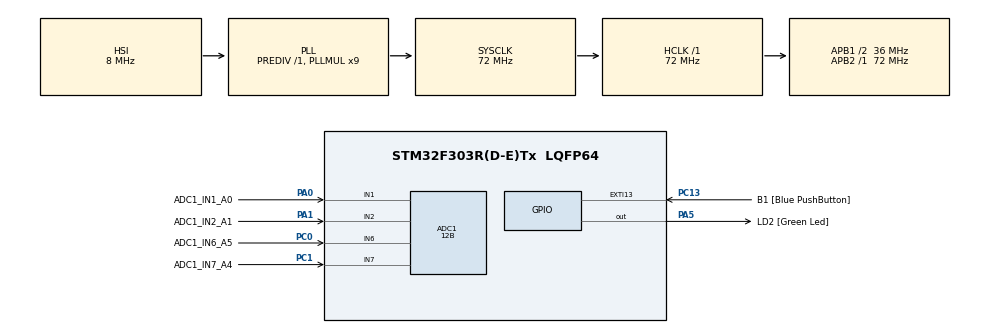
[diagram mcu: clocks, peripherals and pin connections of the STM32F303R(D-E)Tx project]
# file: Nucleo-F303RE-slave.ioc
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ADC1.Channel-0\#ChannelRegularConversion=ADC_CHANNEL_1
ADC1.Channel-1\#ChannelRegularConversion=ADC_CHANNEL_2
ADC1.Channel-2\#ChannelRegularConversion=ADC_CHANNEL_7
ADC1.Channel-3\#ChannelRegularConversion=ADC_CHANNEL_6
ADC1.ClockPrescaler=ADC_CLOCK_ASYNC_DIV1
ADC1.ContinuousConvMode=DISABLE
ADC1.DMAContinuousRequests=ENABLE
ADC1.EOCSelection=ADC_EOC_SEQ_CONV
ADC1.EnableInjectedConversion=DISABLE
ADC1.ExternalTrigConv=ADC_EXTERNALTRIGCONV_T1_CC3
ADC1.ExternalTrigConvEdge=ADC_EXTERNALTRIGCONVEDGE_RISINGFALLING
ADC1.NbrOfConversion=4
ADC1.NbrOfConversionFlag=1
ADC1.Offset-1\#ChannelRegularConversion=0
ADC1.Offset-2\#ChannelRegularConversion=0
ADC1.Offset-3\#ChannelRegularConversion=0
ADC1.OffsetNumber-1\#ChannelRegularConversion=ADC_OFFSET_NONE
ADC1.OffsetNumber-2\#ChannelRegularConversion=ADC_OFFSET_NONE
ADC1.OffsetNumber-3\#ChannelRegularConversion=ADC_OFFSET_NONE
ADC1.Rank-1\#ChannelRegularConversion=2
ADC1.Rank-2\#ChannelRegularConversion=3
ADC1.Rank-3\#ChannelRegularConversion=4
ADC1.Resolution=ADC_RESOLUTION_12B
ADC1.SamplingTime-0\#ChannelRegularConversion=ADC_SAMPLETIME_601CYCLES_5
ADC1.SamplingTime-1\#ChannelRegularConversion=ADC_SAMPLETIME_601CYCLES_5
ADC1.SamplingTime-2\#ChannelRegularConversion=ADC_SAMPLETIME_601CYCLES_5
ADC1.SamplingTime-3\#ChannelRegularConversion=ADC_SAMPLETIME_601CYCLES_5
ADC1.SamplingTimeOPAMP-2\#ChannelRegularConversion=ADC_SAMPLETIME_61CYCLES_5
ADC1.SamplingTimeOPAMP-3\#ChannelRegularConversion=ADC_SAMPLETIME_61CYCLES_5
ADC1.SequencerNbRanks=1
ADC1.master=1
Dma.ADC1.0.Direction=DMA_PERIPH_TO_MEMORY
Dma.ADC1.0.Instance=DMA1_Channel1
Dma.ADC1.0.MemDataAlignment=DMA_MDATAALIGN_HALFWORD
Dma.ADC1.0.MemInc=DMA_MINC_ENABLE
Dma.ADC1.0.Mode=DMA_CIRCULAR
Dma.ADC1.0.PeriphDataAlignment=DMA_PDATAALIGN_HALFWORD
Dma.ADC1.0.PeriphInc=DMA_PINC_DISABLE
Dma.ADC1.0.Priority=DMA_PRIORITY_LOW
Dma.Request0=ADC1
Mcu.Family=STM32F3
Mcu.Name=STM32F303R(D-E)Tx
Mcu.Package=LQFP64
NVIC.DMA1_Channel1_IRQn=true\:0\:0\:false\:false\:true\:false\:true
NVIC.PriorityGroup=NVIC_PRIORITYGROUP_4
PA0.GPIO_Label=ADC1_IN1_A0
PA0.GPIO_Mode=GPIO_MODE_ANALOG
PA0.GPIO_PuPd=GPIO_NOPULL
PA0.Mode=IN1-Single-Ended
PA0.Signal=ADC1_IN1
PA1.GPIO_Label=ADC1_IN2_A1
PA1.Mode=IN2-Single-Ended
PA1.Signal=ADC1_IN2
PA13.GPIO_Label=TMS
PA13.Mode=Serial_Wire
PA13.Signal=SYS_JTMS-SWDIO
PA14.GPIO_Label=TCK
PA14.Mode=Serial_Wire
PA14.Signal=SYS_JTCK-SWCLK
PA5.GPIO_Label=LD2 [Green Led]
PA5.GPIO_Mode=GPIO_MODE_OUTPUT_PP
PA5.GPIO_PuPd=GPIO_NOPULL
PA5.GPIO_Speed=GPIO_SPEED_FREQ_LOW
PA5.Signal=GPIO_Output
PB3.GPIO_Label=SWO
PB3.Signal=SYS_JTDO-TRACESWO
PC0.GPIO_Label=ADC1_IN6_A5
PC0.Signal=ADCx_IN6
PC1.GPIO_Label=ADC1_IN7_A4
PC1.Signal=ADCx_IN7
PC13.GPIO_Label=B1 [Blue PushButton]
PC13.GPIO_ModeDefaultEXTI=GPIO_MODE_IT_FALLING
PC13.Signal=GPXTI13
PC14-OSC32_IN.Mode=LSE-External-Oscillator
PC14-OSC32_IN.Signal=RCC_OSC32_IN
PC15-OSC32_OUT.Mode=LSE-External-Oscillator
PC15-OSC32_OUT.Signal=RCC_OSC32_OUT
PF0-OSC_IN.Mode=HSE-External-Clock-Source
PF0-OSC_IN.Signal=RCC_OSC_IN
PF1-OSC_OUT.Signal=RCC_OSC_OUT
ProjectManager.HeapSize=0x200
ProjectManager.StackSize=0x400
ProjectManager.TargetToolchain=STM32CubeIDE
RCC.AHBFreq_Value=72000000
RCC.APB1CLKDivider=RCC_HCLK_DIV2
RCC.APB1Freq_Value=36000000
RCC.APB1TimFreq_Value=72000000
RCC.APB2Freq_Value=72000000
RCC.APB2TimFreq_Value=72000000
RCC.CortexFreq_Value=72000000
RCC.HCLKFreq_Value=72000000
RCC.HSE_VALUE=8000000
RCC.HSI_VALUE=8000000
RCC.PLLM=8
RCC.PLLMUL=RCC_PLL_MUL9
RCC.PLLN=336
RCC.PLLP=RCC_PLLP_DIV4
RCC.PLLQ=7
RCC.RCC_PLLsource_Clock_Source_FROM_HSE=RCC_HSE_PREDIV_DIV2
RCC.SYSCLKFreq_VALUE=72000000
RCC.SYSCLKSourceVirtual=RCC_SYSCLKSOURCE_PLLCLK
RCC.USBFreq_Value=72000000
SH.ADCx_IN6.0=ADC1_IN6,IN6-Single-Ended
SH.ADCx_IN7.0=ADC1_IN7,IN7-Single-Ended
TIM1.AutoReloadPreload=TIM_AUTORELOAD_PRELOAD_ENABLE
TIM1.Channel-Output\ Compare3\ No\ Output=TIM_CHANNEL_3
TIM1.OCMode_3=TIM_OCMODE_TOGGLE
TIM1.Period=99
TIM1.Prescaler=71
VP_TIM1_VS_ClockSourceINT.Mode=Internal
VP_TIM1_VS_no_output3.Mode=Output Compare3 No Output
board=NUCLEO-F303RE

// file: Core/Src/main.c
/* USER CODE BEGIN Header */
/**
  ******************************************************************************
  * @file           : main.c
  * @brief          : Main program body
  ******************************************************************************
  * @attention
  *
  * <h2><center>&copy; Copyright (c) 2021 STMicroelectronics.
  * All rights reserved.</center></h2>
  *
  * This software component is licensed by ST under BSD 3-Clause license,
  * the "License"; You may not use this file except in compliance with the
  * License. You may obtain a copy of the License at:
  *                        opensource.org/licenses/BSD-3-Clause
  *
  ******************************************************************************
  */
/* USER CODE END Header */
#include "main.h"

ADC_HandleTypeDef hadc1;
DMA_HandleTypeDef hdma_adc1;

TIM_HandleTypeDef htim1;

/* USER CODE BEGIN PV */
extern void multimeter_meas(void);
/* USER CODE END PV */

void SystemClock_Config(void);
static void MX_GPIO_Init(void);
static void MX_DMA_Init(void);
static void MX_ADC1_Init(void);
static void MX_TIM1_Init(void);

int main(void)
{

  /* MCU Configuration--------------------------------------------------------*/

  /* Reset of all peripherals, Initializes the Flash interface and the Systick. */
  HAL_Init();

  /* Configure the system clock */
  SystemClock_Config();

  /* Initialize all configured peripherals */
  MX_GPIO_Init();
  MX_DMA_Init();
  MX_ADC1_Init();
  MX_TIM1_Init();
  /* USER CODE BEGIN 2 */
  multimeter_meas();
  /* USER CODE END 2 */

  /* Infinite loop */
  while (1)
  {

  }
}

void SystemClock_Config(void)
{
  RCC_OscInitTypeDef RCC_OscInitStruct = {0};
  RCC_ClkInitTypeDef RCC_ClkInitStruct = {0};
  RCC_PeriphCLKInitTypeDef PeriphClkInit = {0};

  /** Initializes the RCC Oscillators according to the specified parameters
  * in the RCC_OscInitTypeDef structure.
  */
  RCC_OscInitStruct.OscillatorType = RCC_OSCILLATORTYPE_HSI;
  RCC_OscInitStruct.HSIState = RCC_HSI_ON;
  RCC_OscInitStruct.HSICalibrationValue = RCC_HSICALIBRATION_DEFAULT;
  RCC_OscInitStruct.PLL.PLLState = RCC_PLL_ON;
  RCC_OscInitStruct.PLL.PLLSource = RCC_PLLSOURCE_HSI;
  RCC_OscInitStruct.PLL.PLLMUL = RCC_PLL_MUL9;
  RCC_OscInitStruct.PLL.PREDIV = RCC_PREDIV_DIV1;
  if (HAL_RCC_OscConfig(&RCC_OscInitStruct) != HAL_OK)
  {
    Error_Handler();
  }
  /** Initializes the CPU, AHB and APB buses clocks
  */
  RCC_ClkInitStruct.ClockType = RCC_CLOCKTYPE_HCLK|RCC_CLOCKTYPE_SYSCLK
                              |RCC_CLOCKTYPE_PCLK1|RCC_CLOCKTYPE_PCLK2;
  RCC_ClkInitStruct.SYSCLKSource = RCC_SYSCLKSOURCE_PLLCLK;
  RCC_ClkInitStruct.AHBCLKDivider = RCC_SYSCLK_DIV1;
  RCC_ClkInitStruct.APB1CLKDivider = RCC_HCLK_DIV2;
  RCC_ClkInitStruct.APB2CLKDivider = RCC_HCLK_DIV1;

  if (HAL_RCC_ClockConfig(&RCC_ClkInitStruct, FLASH_LATENCY_2) != HAL_OK)
  {
    Error_Handler();
  }
  PeriphClkInit.PeriphClockSelection = RCC_PERIPHCLK_TIM1|RCC_PERIPHCLK_ADC12;
  PeriphClkInit.Adc12ClockSelection = RCC_ADC12PLLCLK_DIV1;
  PeriphClkInit.Tim1ClockSelection = RCC_TIM1CLK_HCLK;
  if (HAL_RCCEx_PeriphCLKConfig(&PeriphClkInit) != HAL_OK)
  {
    Error_Handler();
  }
}

static void MX_ADC1_Init(void)
{

  ADC_MultiModeTypeDef multimode = {0};
  ADC_ChannelConfTypeDef sConfig = {0};

  /** Common config
  */
  hadc1.Instance = ADC1;
  hadc1.Init.ClockPrescaler = ADC_CLOCK_ASYNC_DIV1;
  hadc1.Init.Resolution = ADC_RESOLUTION_12B;
  hadc1.Init.ScanConvMode = ADC_SCAN_ENABLE;
  hadc1.Init.ContinuousConvMode = DISABLE;
  hadc1.Init.DiscontinuousConvMode = DISABLE;
  hadc1.Init.ExternalTrigConvEdge = ADC_EXTERNALTRIGCONVEDGE_RISINGFALLING;
  hadc1.Init.ExternalTrigConv = ADC_EXTERNALTRIGCONV_T1_CC3;
  hadc1.Init.DataAlign = ADC_DATAALIGN_RIGHT;
  hadc1.Init.NbrOfConversion = 4;
  hadc1.Init.DMAContinuousRequests = ENABLE;
  hadc1.Init.EOCSelection = ADC_EOC_SEQ_CONV;
  hadc1.Init.LowPowerAutoWait = DISABLE;
  hadc1.Init.Overrun = ADC_OVR_DATA_OVERWRITTEN;
  if (HAL_ADC_Init(&hadc1) != HAL_OK)
  {
    Error_Handler();
  }
  /** Configure the ADC multi-mode
  */
  multimode.Mode = ADC_MODE_INDEPENDENT;
  if (HAL_ADCEx_MultiModeConfigChannel(&hadc1, &multimode) != HAL_OK)
  {
    Error_Handler();
  }
  /** Configure Regular Channel
  */
  sConfig.Channel = ADC_CHANNEL_1;
  sConfig.Rank = ADC_REGULAR_RANK_1;
  sConfig.SingleDiff = ADC_SINGLE_ENDED;
  sConfig.SamplingTime = ADC_SAMPLETIME_601CYCLES_5;
  sConfig.OffsetNumber = ADC_OFFSET_NONE;
  sConfig.Offset = 0;
  if (HAL_ADC_ConfigChannel(&hadc1, &sConfig) != HAL_OK)
  {
    Error_Handler();
  }
  /** Configure Regular Channel
  */
  sConfig.Channel = ADC_CHANNEL_2;
  sConfig.Rank = ADC_REGULAR_RANK_2;
  if (HAL_ADC_ConfigChannel(&hadc1, &sConfig) != HAL_OK)
  {
    Error_Handler();
  }
  /** Configure Regular Channel
  */
  sConfig.Channel = ADC_CHANNEL_7;
  sConfig.Rank = ADC_REGULAR_RANK_3;
  if (HAL_ADC_ConfigChannel(&hadc1, &sConfig) != HAL_OK)
  {
    Error_Handler();
  }
  /** Configure Regular Channel
  */
  sConfig.Channel = ADC_CHANNEL_6;
  sConfig.Rank = ADC_REGULAR_RANK_4;
  if (HAL_ADC_ConfigChannel(&hadc1, &sConfig) != HAL_OK)
  {
    Error_Handler();
  }

}

static void MX_TIM1_Init(void)
{

  TIM_ClockConfigTypeDef sClockSourceConfig = {0};
  TIM_MasterConfigTypeDef sMasterConfig = {0};
  TIM_OC_InitTypeDef sConfigOC = {0};
  TIM_BreakDeadTimeConfigTypeDef sBreakDeadTimeConfig = {0};

  htim1.Instance = TIM1;
  htim1.Init.Prescaler = 71;
  htim1.Init.CounterMode = TIM_COUNTERMODE_UP;
  htim1.Init.Period = 99;
  htim1.Init.ClockDivision = TIM_CLOCKDIVISION_DIV1;
  htim1.Init.RepetitionCounter = 0;
  htim1.Init.AutoReloadPreload = TIM_AUTORELOAD_PRELOAD_ENABLE;
  if (HAL_TIM_Base_Init(&htim1) != HAL_OK)
  {
    Error_Handler();
  }
  sClockSourceConfig.ClockSource = TIM_CLOCKSOURCE_INTERNAL;
  if (HAL_TIM_ConfigClockSource(&htim1, &sClockSourceConfig) != HAL_OK)
  {
    Error_Handler();
  }
  if (HAL_TIM_OC_Init(&htim1) != HAL_OK)
  {
    Error_Handler();
  }
  sMasterConfig.MasterOutputTrigger = TIM_TRGO_RESET;
  sMasterConfig.MasterOutputTrigger2 = TIM_TRGO2_RESET;
  sMasterConfig.MasterSlaveMode = TIM_MASTERSLAVEMODE_DISABLE;
  if (HAL_TIMEx_MasterConfigSynchronization(&htim1, &sMasterConfig) != HAL_OK)
  {
    Error_Handler();
  }
  sConfigOC.OCMode = TIM_OCMODE_TOGGLE;
  sConfigOC.Pulse = 0;
  sConfigOC.OCPolarity = TIM_OCPOLARITY_HIGH;
  sConfigOC.OCNPolarity = TIM_OCNPOLARITY_HIGH;
  sConfigOC.OCFastMode = TIM_OCFAST_DISABLE;
  sConfigOC.OCIdleState = TIM_OCIDLESTATE_RESET;
  sConfigOC.OCNIdleState = TIM_OCNIDLESTATE_RESET;
  if (HAL_TIM_OC_ConfigChannel(&htim1, &sConfigOC, TIM_CHANNEL_3) != HAL_OK)
  {
    Error_Handler();
  }
  sBreakDeadTimeConfig.OffStateRunMode = TIM_OSSR_DISABLE;
  sBreakDeadTimeConfig.OffStateIDLEMode = TIM_OSSI_DISABLE;
  sBreakDeadTimeConfig.LockLevel = TIM_LOCKLEVEL_OFF;
  sBreakDeadTimeConfig.DeadTime = 0;
  sBreakDeadTimeConfig.BreakState = TIM_BREAK_DISABLE;
  sBreakDeadTimeConfig.BreakPolarity = TIM_BREAKPOLARITY_HIGH;
  sBreakDeadTimeConfig.BreakFilter = 0;
  sBreakDeadTimeConfig.Break2State = TIM_BREAK2_DISABLE;
  sBreakDeadTimeConfig.Break2Polarity = TIM_BREAK2POLARITY_HIGH;
  sBreakDeadTimeConfig.Break2Filter = 0;
  sBreakDeadTimeConfig.AutomaticOutput = TIM_AUTOMATICOUTPUT_DISABLE;
  if (HAL_TIMEx_ConfigBreakDeadTime(&htim1, &sBreakDeadTimeConfig) != HAL_OK)
  {
    Error_Handler();
  }

}

static void MX_DMA_Init(void)
{

  /* DMA controller clock enable */
  __HAL_RCC_DMA1_CLK_ENABLE();

  /* DMA interrupt init */
  /* DMA1_Channel1_IRQn interrupt configuration */
  HAL_NVIC_SetPriority(DMA1_Channel1_IRQn, 0, 0);
  HAL_NVIC_EnableIRQ(DMA1_Channel1_IRQn);

}

static void MX_GPIO_Init(void)
{
  GPIO_InitTypeDef GPIO_InitStruct = {0};

  /* GPIO Ports Clock Enable */
  __HAL_RCC_GPIOC_CLK_ENABLE();
  __HAL_RCC_GPIOF_CLK_ENABLE();
  __HAL_RCC_GPIOA_CLK_ENABLE();
  __HAL_RCC_GPIOB_CLK_ENABLE();

  /*Configure GPIO pin Output Level */
  HAL_GPIO_WritePin(GPIOA, LD2_Pin|SWITCH_Pin, GPIO_PIN_RESET);

  /*Configure GPIO pin : B1_Pin */
  GPIO_InitStruct.Pin = B1_Pin;
  GPIO_InitStruct.Mode = GPIO_MODE_IT_FALLING;
  GPIO_InitStruct.Pull = GPIO_NOPULL;
  HAL_GPIO_Init(B1_GPIO_Port, &GPIO_InitStruct);

  /*Configure GPIO pins : LD2_Pin SWITCH_Pin */
  GPIO_InitStruct.Pin = LD2_Pin|SWITCH_Pin;
  GPIO_InitStruct.Mode = GPIO_MODE_OUTPUT_PP;
  GPIO_InitStruct.Pull = GPIO_NOPULL;
  GPIO_InitStruct.Speed = GPIO_SPEED_FREQ_LOW;
  HAL_GPIO_Init(GPIOA, &GPIO_InitStruct);

}

void Error_Handler(void)
{
  __disable_irq();
  while (1)
  {
  }
}
